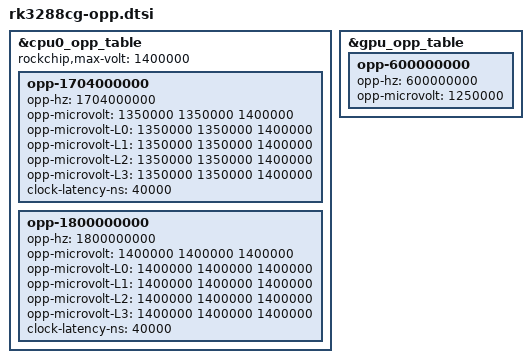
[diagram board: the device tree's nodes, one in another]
// SPDX-License-Identifier: (GPL-2.0+ OR MIT)
/*
 * Copyright (c) 2018 Fuzhou Rockchip Electronics Co., Ltd
 */

&cpu0_opp_table {
	rockchip,max-volt = <1400000>;
	opp-1704000000 {
		opp-hz = /bits/ 64 <1704000000>;
		opp-microvolt = <1350000 1350000 1400000>;
		opp-microvolt-L0 = <1350000 1350000 1400000>;
		opp-microvolt-L1 = <1350000 1350000 1400000>;
		opp-microvolt-L2 = <1350000 1350000 1400000>;
		opp-microvolt-L3 = <1350000 1350000 1400000>;
		clock-latency-ns = <40000>;
	};
	opp-1800000000 {
		opp-hz = /bits/ 64 <1800000000>;
		opp-microvolt = <1400000 1400000 1400000>;
		opp-microvolt-L0 = <1400000 1400000 1400000>;
		opp-microvolt-L1 = <1400000 1400000 1400000>;
		opp-microvolt-L2 = <1400000 1400000 1400000>;
		opp-microvolt-L3 = <1400000 1400000 1400000>;
		clock-latency-ns = <40000>;
	};
};

&gpu_opp_table {
	opp-600000000 {
		opp-hz = /bits/ 64 <600000000>;
		opp-microvolt = <1250000>;
	};
};
